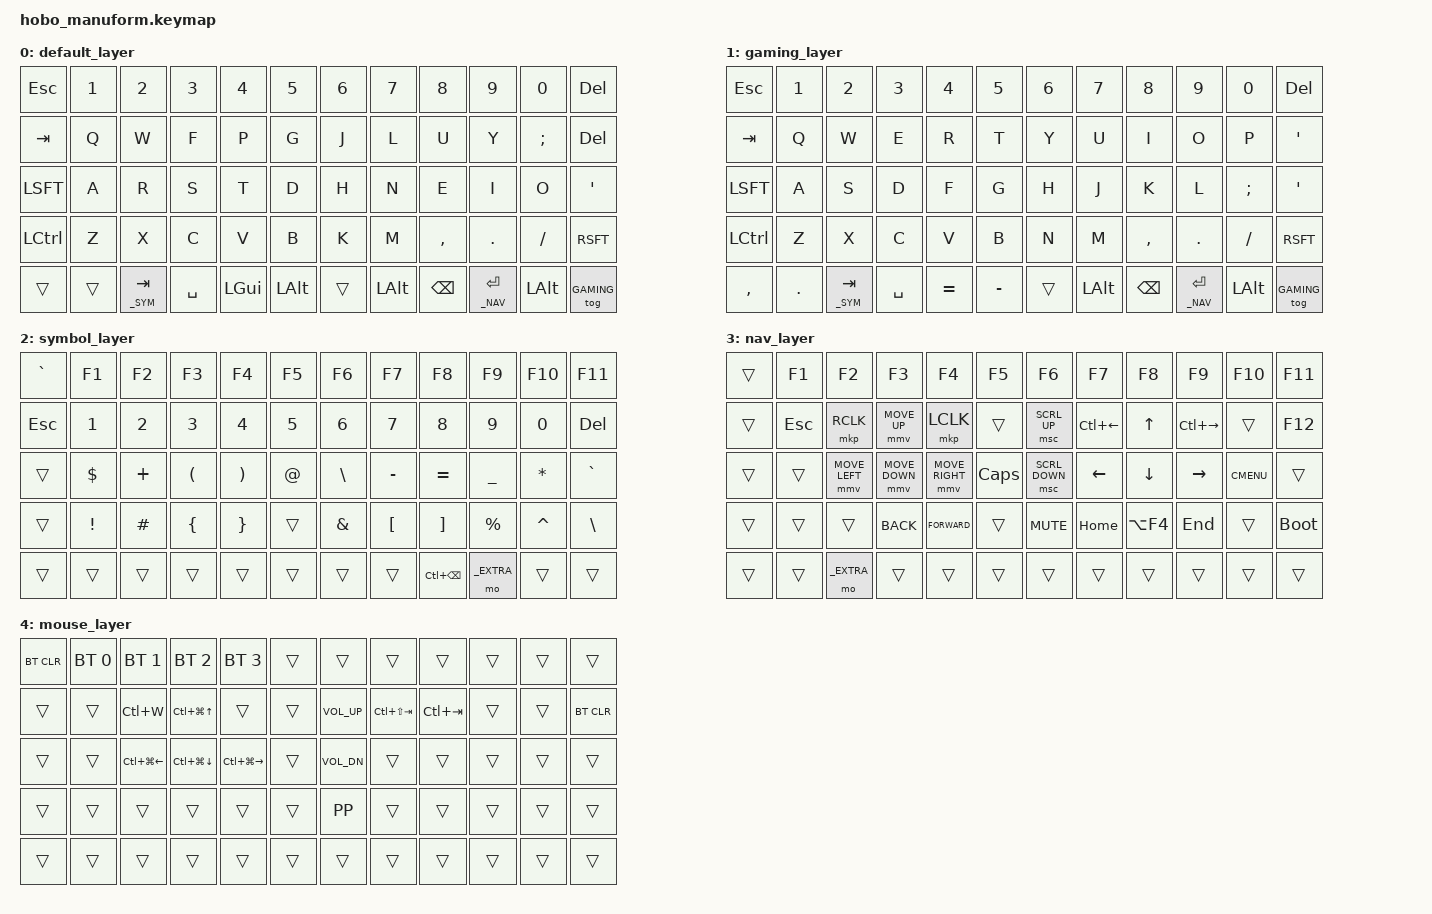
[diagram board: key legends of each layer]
#include <behaviors.dtsi>
#include <dt-bindings/zmk/keys.h>
#include <dt-bindings/zmk/bt.h>
#include <dt-bindings/zmk/mouse.h>

#define ZMK_POINTING_DEFAULT_MOVE_VAL 1500  // default: 600
#define ZMK_POINTING_DEFAULT_SCRL_VAL 35    // default: 10

#include <dt-bindings/zmk/pointing.h>

// Layer definitions
#define _BASE 0
#define _GAMING 1
#define _SYM  2
#define _NAV  3
#define _EXTRA 4
#define _MOUSE 5

// Define a tapping term for our Layer-Tap keys.
#define TAPPING_TERM 200
// Define a quick tapping term for combos.
#define COMBO_TERM 40

/ {
    behaviors {
        // // Left Hand: Layer-Tap Tab -> Symbol Layer
        // lt_sym_tab: layer_tap_tab {
        //     compatible = "zmk,behavior-layer-tap";
        //     #binding-cells = <2>;
        //     bindings = <&mo _SYM>, <&kp TAB>;
        //     tapping-term-ms = <TAPPING_TERM>;
        // };

        // // Right Hand: Layer-Tap Enter -> Navigation Layer
        // lt_nav_enter: layer_tap_enter {
        //     compatible = "zmk,behavior-layer-tap";
        //     #binding-cells = <2>;
        //     bindings = <&mo _NAV>, <&kp ENTER>;
        //     tapping-term-ms = <TAPPING_TERM>;
        // };
    };
    // Define the mouse layer behavior
    behaviors {
        mouse_layer_behavior: mouse_layer {
            compatible = "zmk,behavior-mouse-layer";
            #binding-cells = <0>;
            move-steps = <ZMK_POINTING_DEFAULT_MOVE_VAL>;
            scroll-steps = <ZMK_POINTING_DEFAULT_SCRL_VAL>;
            
        };

        lt: layer_tap {
            compatible = "zmk,behavior-hold-tap";
            #binding-cells = <2>;
            flavor = "hold-preferred";
            tapping-term-ms = <200>;
            bindings = <&mo>, <&kp>;
            display-name = "Layer-Tap";
        };
    };
    // Define the combos
    combos {
        
        compatible = "zmk,combos";

        combo_win_o {
            timeout-ms = <40>;
            // triggers one time shift when pressing N and backspace
            key-positions = <34 56>;
            bindings = <&sk LGUI>;
            layers = <_BASE>;
        };

        combo_alt_i {
            timeout-ms = <40>;
            // triggers one time shift when pressing N and backspace
            key-positions = <33 56>;
            bindings = <&sk LALT>;
            layers = <_BASE>;
        };
        
        combo_shift_e {
            timeout-ms = <40>;
            // triggers one time shift when pressing N and backspace
            key-positions = <32 56>;
            bindings = <&sk LSHIFT>;
            layers = <_BASE>;
        };

        combo_ctrl_n {
            timeout-ms = <40>;
            // triggers one time shift when pressing N and backspace
            key-positions = <31 56>;
            bindings = <&sk LCTRL>;
            layers = <_BASE>;
        };



        combo_win_a {
            timeout-ms = <40>;
            // triggers one time shift when pressing N and backspace
            key-positions = <25 51>;
            bindings = <&sk LGUI>;
            layers = <_BASE>;
        };

        combo_alt_r {
            timeout-ms = <40>;
            // triggers one time shift when pressing N and backspace
            key-positions = <26 51>;
            bindings = <&sk LALT>;
            layers = <_BASE>;
        };
        
        combo_shift_s {
            timeout-ms = <40>;
            // triggers one time shift when pressing N and backspace
            key-positions = <27 51>;
            bindings = <&sk LSHIFT>;
            layers = <_BASE>;
        };

        combo_ctrl_t {
            timeout-ms = <40>;
            // triggers one time shift when pressing N and backspace
            key-positions = <28 51>;
            bindings = <&sk LCTRL>;
            layers = <_BASE>;
        };
    };

    // PER LA THUMB CLUSTER, CONTARE PER ENTRAMBE LE METÁ DA IN BASSO A SINISTRA, VERSO L'ALTO A DESTRA
    // FINO IN FONDO A DESTRA.

    keymap {
        compatible = "zmk,keymap";

                default_layer {
            bindings = <
            // Main blocks (48 keys)
            &kp ESC  &kp N1    &kp N2    &kp N3    &kp N4    &kp N5      &kp N6    &kp N7    &kp N8    &kp N9    &kp N0    &kp DEL
            &kp TAB    &kp Q     &kp W     &kp F     &kp P     &kp G       &kp J     &kp L     &kp U     &kp Y     &kp SEMI  &kp DEL
            &kp LSFT   &kp A     &kp R     &kp S     &kp T     &kp D       &kp H     &kp N     &kp E     &kp I     &kp O     &kp SQT
            &kp LCTRL  &kp Z     &kp X     &kp C     &kp V     &kp B       &kp K     &kp M     &kp COMMA &kp DOT   &kp FSLH  &kp RSFT

            // Thumb clusters (12 keys)
            // The order here matches the dtsi: inner key first for the left hand.
            
            &trans   &trans   &lt _SYM TAB &kp SPACE &kp LGUI  &kp LALT    &trans    &kp LALT    &kp BSPC  &lt _NAV ENTER  &kp LEFT_ALT &tog _GAMING
            >;
            // TODO now the lt shit says it aint there.
        };
    
                gaming_layer {
            bindings = <

            &kp ESC  &kp N1    &kp N2    &kp N3    &kp N4    &kp N5      &kp N6    &kp N7    &kp N8    &kp N9    &kp N0    &kp DEL
            &kp TAB    &kp Q     &kp W     &kp E    &kp R     &kp T       &kp Y     &kp U     &kp I     &kp O     &kp P     &kp SQT
            &kp LSFT   &kp A     &kp S     &kp D     &kp F     &kp G       &kp H     &kp J     &kp K     &kp L     &kp SEMI  &kp SQT
            &kp LCTRL  &kp Z     &kp X     &kp C     &kp V     &kp B       &kp N     &kp M     &kp COMMA &kp DOT   &kp FSLH  &kp RSFT
            &kp COMMA   &kp DOT   &lt _SYM TAB &kp SPACE &kp EQUAL  &kp MINUS    &trans    &kp LALT    &kp BSPC  &lt _NAV ENTER  &kp LEFT_ALT &tog _GAMING
            >;
    };

        symbol_layer {
            bindings = <
            
            &kp GRAVE  &kp F1    &kp F2    &kp F3    &kp F4    &kp F5      &kp F6    &kp F7    &kp F8    &kp F9    &kp F10   &kp F11
            &kp ESC    &kp N1    &kp N2    &kp N3    &kp N4    &kp N5      &kp N6    &kp N7    &kp N8    &kp N9    &kp N0    &kp DEL
            &trans     &kp DLLR  &kp PLUS  &kp LPAR  &kp RPAR  &kp AT      &kp BSLH  &kp MINUS &kp EQUAL &kp UNDER &kp STAR  &kp GRAVE
            &trans     &kp EXCL  &kp HASH  &kp LBRC  &kp RBRC  &trans      &kp AMPS  &kp LBKT  &kp RBKT  &kp PRCNT &kp CARET &kp BSLH


            &trans     &trans    &trans    &trans    &trans    &trans      &trans    &trans    &kp LC(BSPC)    &mo _EXTRA     &trans    &trans
            >;
        };

        nav_layer {
            bindings = <
            
            &trans     &kp F1      &kp F2           &kp F3          &kp F4          &kp F5              &kp F6          &kp F7    &kp F8      &kp F9    &kp F10   &kp F11
            &trans     &kp ESC     &mkp RCLK        &mmv MOVE_UP    &mkp LCLK       &trans        &msc SCRL_UP  &kp LC(LEFT)&kp UP     &kp LC(RIGHT)&trans  &kp F12
            &trans     &trans      &mmv MOVE_LEFT   &mmv MOVE_DOWN  &mmv MOVE_RIGHT &kp CAPS            &msc SCRL_DOWN    &kp LEFT  &kp DOWN    &kp RIGHT &kp K_CMENU    &trans
            &trans     &trans      &trans           &kp K_BACK      &kp K_FORWARD   &trans              &kp C_MUTE      &kp HOME  &kp LA(F4)      &kp END  &trans     &bootloader


            &trans     &trans    &mo _EXTRA    &trans    &trans    &trans                   &trans    &trans    &trans    &trans    &trans    &trans 
            >;
        };
// da aggiungere roba con &bt
        mouse_layer {
            bindings = <

            &bt BT_CLR      &bt BT_SEL 0      &bt BT_SEL 1    &bt BT_SEL 2    &bt BT_SEL 3    &trans                    &trans          &trans    &trans    &trans    &trans    &trans
            &trans      &trans      &kp LC(W) &kp LC(LG(UP))&trans &trans      &kp C_VOL_UP    &kp LC(LS(TAB)) &kp LC(TAB)    &trans    &trans    &bt BT_CLR
            &trans      &trans      &kp LC(LG(LEFT))    &kp LC(LG(DOWN)) &kp LC(LG(RIGHT))    &trans                    &kp C_VOL_DN    &trans    &trans    &trans    &trans    &trans
            &trans      &trans      &trans    &trans    &trans    &trans                    &kp K_PP        &trans    &trans    &trans    &trans    &trans
            
            &trans      &trans          &trans    &trans    &trans    &trans                &trans    &trans    &trans    &trans    &trans    &trans
            >;
        };


    };
};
